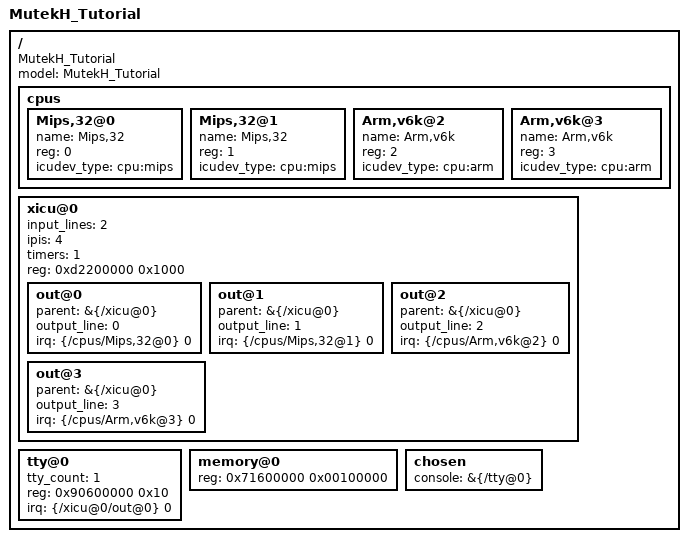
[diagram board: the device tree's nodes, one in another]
/dts-v1/;

/ {
	model = "MutekH_Tutorial";
	compatible = "MutekH_Tutorial";
	#address-cells = <1>;
	#size-cells = <1>;

	cpus {
		#address-cells = <1>;
		#size-cells = <0>;
		Mips,32@0 {
			name = "Mips,32";
			device_type = "cpu";
			reg = <0>;
			icudev_type = "cpu:mips";
		};

		Mips,32@1 {
			name = "Mips,32";
			device_type = "cpu";
			reg = <1>;
			icudev_type = "cpu:mips";
		};

		Arm,v6k@2 {
			name = "Arm,v6k";
			device_type = "cpu";
			reg = <2>;
			icudev_type = "cpu:arm";
		};

		Arm,v6k@3 {
			name = "Arm,v6k";
			device_type = "cpu";
			reg = <3>;
			icudev_type = "cpu:arm";
		};

	};

	xicu@0 {
	    device_type = "soclib:xicu:root";
		input_lines = <2>;
		ipis = <4>;
		timers = <1>;
		reg = <0xd2200000 0x1000>;

	    	out@0 {
	    	    device_type = "soclib:xicu:filter";
	    	    parent = &{/xicu@0};
	    		output_line = <0>;
	    		irq = <&{/cpus/Mips,32@0} 0>;
	    	};
	    
	    	out@1 {
	    	    device_type = "soclib:xicu:filter";
	    	    parent = &{/xicu@0};
	    		output_line = <1>;
	    		irq = <&{/cpus/Mips,32@1} 0>;
	    	};
	    
	    	out@2 {
	    	    device_type = "soclib:xicu:filter";
	    	    parent = &{/xicu@0};
	    		output_line = <2>;
	    		irq = <&{/cpus/Arm,v6k@2} 0>;
	    	};
	    
	    	out@3 {
	    	    device_type = "soclib:xicu:filter";
	    	    parent = &{/xicu@0};
	    		output_line = <3>;
	    		irq = <&{/cpus/Arm,v6k@3} 0>;
	    	};
	};

	tty@0 {
	    device_type = "soclib:tty";
		tty_count = <1>;
		reg = <0x90600000 0x10>;
 		irq = <&{/xicu@0/out@0} 0>;
	};

	memory@0 {
		device_type = "memory";
		memreg: reg = <0x71600000 0x00100000>;
	};

	chosen {
		console = &{/tty@0};
	};

};
